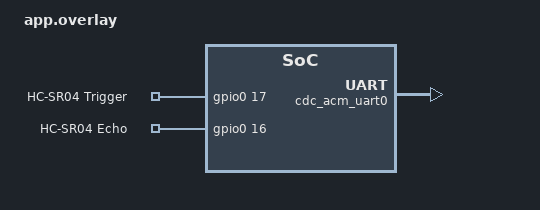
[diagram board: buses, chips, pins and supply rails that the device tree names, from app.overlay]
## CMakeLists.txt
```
# SPDX-License-Identifier: Apache-2.0

cmake_minimum_required(VERSION 3.20.0)

find_package(Zephyr REQUIRED HINTS $ENV{ZEPHYR_BASE})
project(picow_us)

target_sources(app PRIVATE src/main.c)
```

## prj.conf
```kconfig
#CDC specific configurations
CONFIG_USB_DEVICE_STACK=y
CONFIG_USB_DEVICE_PRODUCT="RPi Pico USB Serial Console"
CONFIG_USB_DEVICE_VID=0001
CONFIG_CONSOLE=y

#GPIO specific configurations
CONFIG_GPIO=y #Enables the use of GPIO pins

#PWM specific configurations 
CONFIG_PWM=y # Enables PWM drivers
#CONFIG_PWM_CAPTURE=n #This disables PWM capture mode, which is not needed for motor control and can save some memory.

#UART specific configurations - also required for CDC ACM
CONFIG_SERIAL=y # Enable options for serial drivers
CONFIG_UART_CONSOLE=y # Sets the default for printk and printf to output to the UART serial console
CONFIG_UART_LINE_CTRL=y # This enables the API for apps to control the serial line, such as baud rate, CTS and RTS.
```

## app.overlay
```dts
/ {
    chosen {
        zephyr,console = &cdc_acm_uart0;
    };

    hcsr04 {
        compatible = "gpio-keys";
        trig_pin_label: trig_pin {
            gpios = <&gpio0 17 GPIO_ACTIVE_HIGH>;
            label = "HC-SR04 Trigger";
        };
        echo_pin_label: echo_pin {
            gpios = <&gpio0 16 GPIO_ACTIVE_HIGH>;
            label = "HC-SR04 Echo";
        };
    };

};

&zephyr_udc0 {
    cdc_acm_uart0: cdc_acm_uart0 {
        compatible = "zephyr,cdc-acm-uart";
        label = "CDC_ACM_0";
        status = "okay";
    };
};
```

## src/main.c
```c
#include <zephyr/kernel.h>
#include <zephyr/drivers/gpio.h>
#include <zephyr/usb/usb_device.h>
#include <zephyr/drivers/uart.h>

#define TRIGGER_NODE DT_NODELABEL(trig_pin_label)
#define ECHO_NODE DT_NODELABEL(echo_pin_label)

static const struct gpio_dt_spec trigger = GPIO_DT_SPEC_GET(TRIGGER_NODE, gpios);
static const struct gpio_dt_spec echo = GPIO_DT_SPEC_GET(ECHO_NODE, gpios);

static const struct device *usb_acm = DEVICE_DT_GET(DT_CHOSEN(zephyr_console));

//Function to measure distance
static int measure_distance(void){
    //Set TRIG low for a short duration to ensure a clean signal
    gpio_pin_set_dt(&trigger, 0);
    k_sleep(K_USEC(2));

    //Send a 10 us high pulse to TRIG to start measurement
    gpio_pin_set_dt(&trigger, 1);
    k_sleep(K_USEC(10));
    gpio_pin_set_dt(&trigger, 0);

    //Measure the Pulse width on ECHO
    uint32_t pulse_start = k_cycle_get_32();
    while(gpio_pin_get_dt(&echo) == 0){
        pulse_start = k_cycle_get_32();
    }

    uint32_t pulse_end = k_cycle_get_32();
    while(gpio_pin_get_dt(&echo) == 1){
        pulse_end = k_cycle_get_32();
    }

    // Calculate Duration of High Pulses with overflow handling 
    uint32_t pulse_duration; 
    if (pulse_end >= pulse_start) { 
        pulse_duration = pulse_end - pulse_start; 
    } else { 
        pulse_duration = (UINT32_MAX - pulse_start) + pulse_end + 1; 
    }
    
    //Convert to Microseconds
    uint32_t pulse_duration_us = k_cyc_to_us_near32(pulse_duration);

    //Calculate Distance in centimeters (speed of sound = 34300 cm/s)
    int distance = (pulse_duration_us * 34300) / (2 * 1000000);

    return distance;
}

int main(void)
{ 
    int ret;
    
    if (!device_is_ready(usb_acm)) {
        printk("CDC ACM device not ready\r\n");
        return 0;
    }

    if(!device_is_ready(trigger.port) || !device_is_ready(echo.port)){
        printk("GPIO Device is not ready!\r\n");
        return 0;
    }
    ret = gpio_pin_configure_dt(&trigger, GPIO_OUTPUT);
    if (ret != 0) {
        printk("Error %d: Failed to configure trigger pin\n", ret);
        return 0;
    }

    ret = gpio_pin_configure_dt(&echo, GPIO_INPUT);
    if (ret != 0) {
        printk("Error %d: Failed to configure echo pin\n", ret);
        return 0;
    }

    ret = usb_enable(NULL);
    if (ret != 0) {
        printk("Failed to enable USB\n");
        return 0;
    }

    /* Wait for the USB connection */
    k_sleep(K_SECONDS(1));

    while(1){
        int distance = measure_distance();
        char buffer[64];
       
        //Presents the Output in a cleaner manner by just updating the value
        int len = snprintf(buffer, sizeof(buffer),
                           "\033[2J\033[H"
                           "Ultrasonic Sensor Test\r\n\r\n"
                           "Distance: %d cm\r\n", distance);

        uart_fifo_fill(usb_acm, (uint8_t *) buffer, len);

        k_sleep(K_MSEC(400));
    }

    return 0;
}
```
